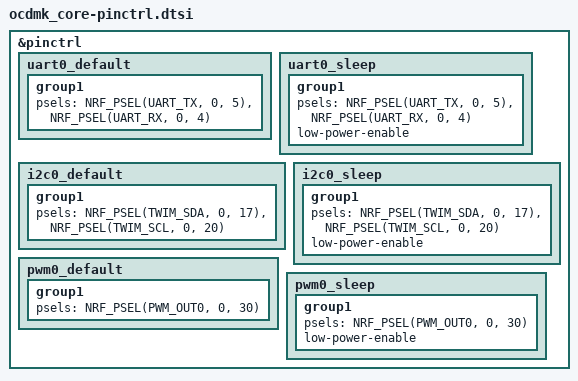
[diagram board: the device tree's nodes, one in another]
/*
 * Copyright (c) 2024 OCDMK Contributors
 *
 * SPDX-License-Identifier: MIT
 *
 * OCDMK Core Pin Control Configuration
 */

&pinctrl {
    /* UART0: TX on P0.05, RX on P0.04 */
    uart0_default: uart0_default {
        group1 {
            psels = <NRF_PSEL(UART_TX, 0, 5)>,
                    <NRF_PSEL(UART_RX, 0, 4)>;
        };
    };

    uart0_sleep: uart0_sleep {
        group1 {
            psels = <NRF_PSEL(UART_TX, 0, 5)>,
                    <NRF_PSEL(UART_RX, 0, 4)>;
            low-power-enable;
        };
    };

    /* I2C0: SDA on P0.17, SCL on P0.20 (optional, adjust as needed) */
    i2c0_default: i2c0_default {
        group1 {
            psels = <NRF_PSEL(TWIM_SDA, 0, 17)>,
                    <NRF_PSEL(TWIM_SCL, 0, 20)>;
        };
    };

    i2c0_sleep: i2c0_sleep {
        group1 {
            psels = <NRF_PSEL(TWIM_SDA, 0, 17)>,
                    <NRF_PSEL(TWIM_SCL, 0, 20)>;
            low-power-enable;
        };
    };

    /* PWM0: LED on P0.30 (controls MCP1662 LED boost driver) */
    pwm0_default: pwm0_default {
        group1 {
            psels = <NRF_PSEL(PWM_OUT0, 0, 30)>;
        };
    };

    pwm0_sleep: pwm0_sleep {
        group1 {
            psels = <NRF_PSEL(PWM_OUT0, 0, 30)>;
            low-power-enable;
        };
    };
};

